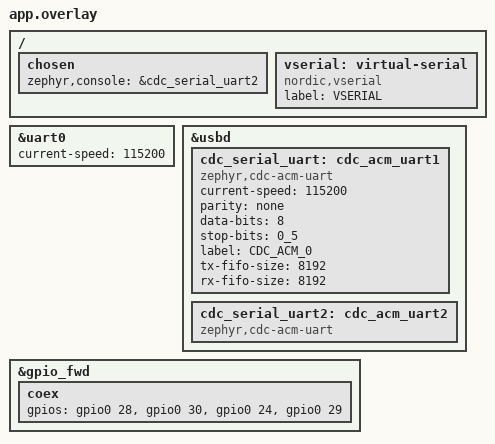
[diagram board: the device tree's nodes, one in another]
&uart0 {
    status = "okay";
    current-speed = <115200>; // Set baud rate
};


zephyr_udc0: &usbd {
    status = "okay";
    cdc_serial_uart: cdc_acm_uart1 { // This creates an instance named "CDC_ACM_0"
        compatible = "zephyr,cdc-acm-uart";
		current-speed = <115200>;
		parity = "none";
		data-bits = <8>;
		stop-bits = "0_5";
        label = "CDC_ACM_0";
        /* Must hold a full protocol frame (4 B header + 4096 B payload =
         * 4100 B; next power of two is 8192). The CDC ACM driver's
         * poll_out silently discards bytes when this ring is full, so any
         * smaller value truncates large frames (e.g. SCAN_DONE
         * notifications) whenever the host drains the USB endpoint slower
         * than the ring fills.
         */
        tx-fifo-size = <8192>;
        rx-fifo-size = <8192>;
        status = "okay";
    };
    cdc_serial_uart2: cdc_acm_uart2 { // This creates an instance named "CDC_ACM_1"
        compatible = "zephyr,cdc-acm-uart";
    };
};
/* Forward the nRF7002 Wi-Fi PTA (coexistence) pins to the network core.
 * The network core drives them from the nrf_radio_coex node in its
 * devicetree (MPSL_CX_NRF700X), arbitrating RF access between the
 * nRF5340 Bluetooth radio and the nRF7002 Wi-Fi radio.
 */
&gpio_fwd {
    coex {
        gpios = <&gpio0 28 0>,  /* COEX_REQ */
                <&gpio0 30 0>,  /* COEX_STATUS0 */
                <&gpio0 24 0>,  /* COEX_GRANT */
                <&gpio0 29 0>;  /* SWCTRL1 */
    };
};

/ {
     chosen {
         zephyr,console = &cdc_serial_uart2;
     };

     vserial: virtual-serial {
         compatible = "nordic,vserial";
         status = "okay";
         label = "VSERIAL";
     };
};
